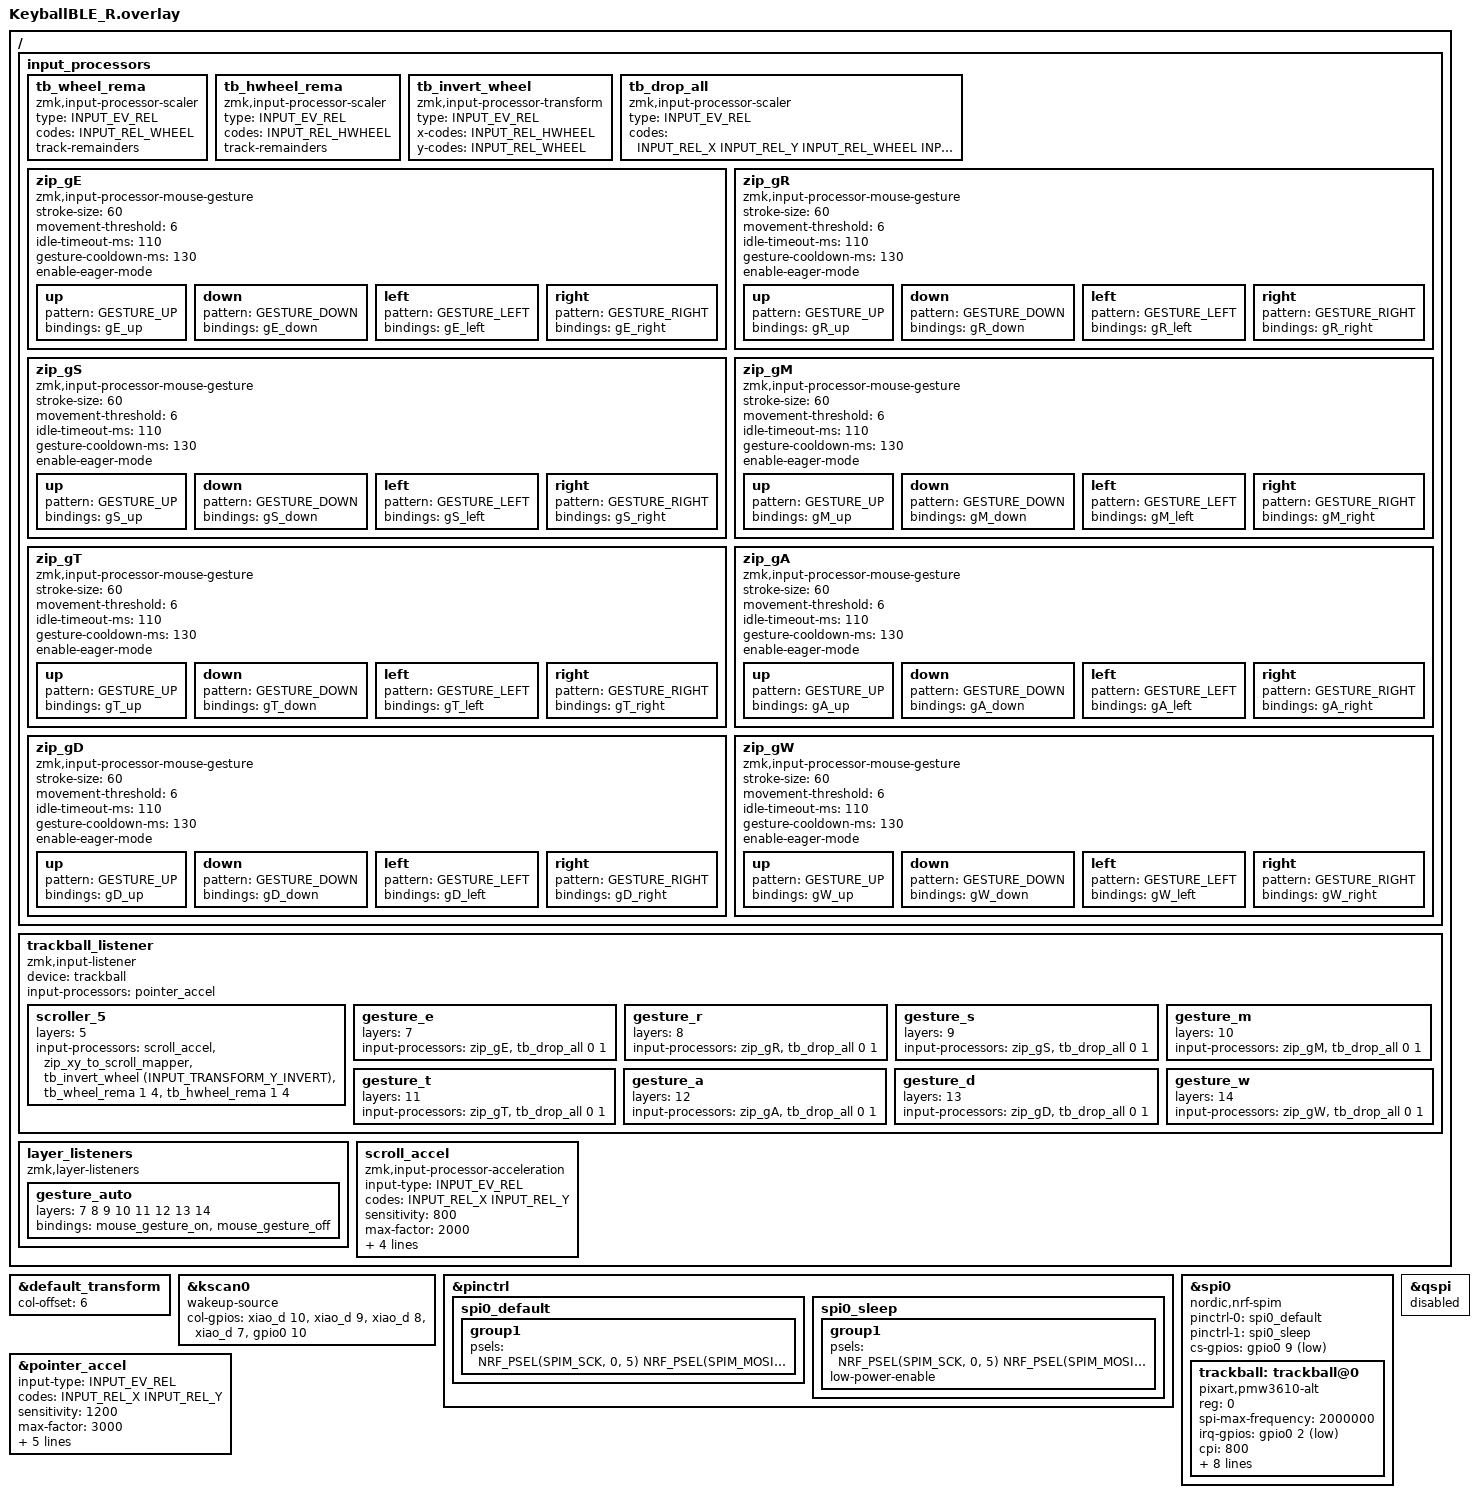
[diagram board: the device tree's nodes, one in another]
/* ===============================
 * KeyballBLE_R.overlay
 *
 *  - SCROLL(layer5)  : overlay side (zip_xy_to_scroll_mapper)
 *  - SNIPE(layer15)  : driver side (snipe-layers)
 *  - gesture(7-14)   : gesture recognition + REL stop
 *  - arrows(layer3)  : trackball to arrow keys
 * =============================== */

#include "KeyballBLE.dtsi"

#include <input/processors.dtsi>
#include <mouse-gesture.dtsi>
#include <behaviors/input_gestures_accel.dtsi>

#include <zephyr/dt-bindings/input/input-event-codes.h>
#include <dt-bindings/gpio/gpio.h>
#include <dt-bindings/zmk/keys.h>
#include <dt-bindings/zmk/mouse.h>
#include <dt-bindings/zmk/input_transform.h>

&default_transform { col-offset = <6>; };

&kscan0 {
    wakeup-source;
    col-gpios =
        <&xiao_d 10 GPIO_ACTIVE_HIGH>,
        <&xiao_d 9  GPIO_ACTIVE_HIGH>,
        <&xiao_d 8  GPIO_ACTIVE_HIGH>,
        <&xiao_d 7  GPIO_ACTIVE_HIGH>,
        <&gpio0  10 GPIO_ACTIVE_HIGH>;
};

/ {
    input_processors {
        tb_wheel_rema: tb_wheel_rema {
            compatible = "zmk,input-processor-scaler";
            #input-processor-cells = <2>;
            type = <INPUT_EV_REL>;
            codes = <INPUT_REL_WHEEL>;
            track-remainders;
        };

        tb_hwheel_rema: tb_hwheel_rema {
            compatible = "zmk,input-processor-scaler";
            #input-processor-cells = <2>;
            type = <INPUT_EV_REL>;
            codes = <INPUT_REL_HWHEEL>;
            track-remainders;
        };

        tb_invert_wheel: tb_invert_wheel {
            compatible = "zmk,input-processor-transform";
            #input-processor-cells = <1>;
            type = <INPUT_EV_REL>;
            x-codes = <INPUT_REL_HWHEEL>;
            y-codes = <INPUT_REL_WHEEL>;
        };

        tb_drop_all: tb_drop_all {
            compatible = "zmk,input-processor-scaler";
            #input-processor-cells = <2>;
            type = <INPUT_EV_REL>;
            codes = <INPUT_REL_X INPUT_REL_Y INPUT_REL_WHEEL INPUT_REL_HWHEEL>;
        };

        zip_gE: zip_gE {
            compatible = "zmk,input-processor-mouse-gesture";
            #input-processor-cells = <0>;
            stroke-size = <60>;
            movement-threshold = <6>;
            idle-timeout-ms = <110>;
            gesture-cooldown-ms = <130>;
            enable-eager-mode;
            up    { pattern = <GESTURE_UP>;    bindings = <&gE_up>;    };
            down  { pattern = <GESTURE_DOWN>;  bindings = <&gE_down>;  };
            left  { pattern = <GESTURE_LEFT>;  bindings = <&gE_left>;  };
            right { pattern = <GESTURE_RIGHT>; bindings = <&gE_right>; };
        };

        zip_gR: zip_gR {
            compatible = "zmk,input-processor-mouse-gesture";
            #input-processor-cells = <0>;
            stroke-size = <60>;
            movement-threshold = <6>;
            idle-timeout-ms = <110>;
            gesture-cooldown-ms = <130>;
            enable-eager-mode;
            up    { pattern = <GESTURE_UP>;    bindings = <&gR_up>;    };
            down  { pattern = <GESTURE_DOWN>;  bindings = <&gR_down>;  };
            left  { pattern = <GESTURE_LEFT>;  bindings = <&gR_left>;  };
            right { pattern = <GESTURE_RIGHT>; bindings = <&gR_right>; };
        };

        zip_gS: zip_gS {
            compatible = "zmk,input-processor-mouse-gesture";
            #input-processor-cells = <0>;
            stroke-size = <60>;
            movement-threshold = <6>;
            idle-timeout-ms = <110>;
            gesture-cooldown-ms = <130>;
            enable-eager-mode;
            up    { pattern = <GESTURE_UP>;    bindings = <&gS_up>;    };
            down  { pattern = <GESTURE_DOWN>;  bindings = <&gS_down>;  };
            left  { pattern = <GESTURE_LEFT>;  bindings = <&gS_left>;  };
            right { pattern = <GESTURE_RIGHT>; bindings = <&gS_right>; };
        };

        zip_gM: zip_gM {
            compatible = "zmk,input-processor-mouse-gesture";
            #input-processor-cells = <0>;
            stroke-size = <60>;
            movement-threshold = <6>;
            idle-timeout-ms = <110>;
            gesture-cooldown-ms = <130>;
            enable-eager-mode;
            up    { pattern = <GESTURE_UP>;    bindings = <&gM_up>;    };
            down  { pattern = <GESTURE_DOWN>;  bindings = <&gM_down>;  };
            left  { pattern = <GESTURE_LEFT>;  bindings = <&gM_left>;  };
            right { pattern = <GESTURE_RIGHT>; bindings = <&gM_right>; };
        };

        zip_gT: zip_gT {
            compatible = "zmk,input-processor-mouse-gesture";
            #input-processor-cells = <0>;
            stroke-size = <60>;
            movement-threshold = <6>;
            idle-timeout-ms = <110>;
            gesture-cooldown-ms = <130>;
            enable-eager-mode;
            up    { pattern = <GESTURE_UP>;    bindings = <&gT_up>;    };
            down  { pattern = <GESTURE_DOWN>;  bindings = <&gT_down>;  };
            left  { pattern = <GESTURE_LEFT>;  bindings = <&gT_left>;  };
            right { pattern = <GESTURE_RIGHT>; bindings = <&gT_right>; };
        };

        zip_gA: zip_gA {
            compatible = "zmk,input-processor-mouse-gesture";
            #input-processor-cells = <0>;
            stroke-size = <60>;
            movement-threshold = <6>;
            idle-timeout-ms = <110>;
            gesture-cooldown-ms = <130>;
            enable-eager-mode;
            up    { pattern = <GESTURE_UP>;    bindings = <&gA_up>;    };
            down  { pattern = <GESTURE_DOWN>;  bindings = <&gA_down>;  };
            left  { pattern = <GESTURE_LEFT>;  bindings = <&gA_left>;  };
            right { pattern = <GESTURE_RIGHT>; bindings = <&gA_right>; };
        };

        zip_gD: zip_gD {
            compatible = "zmk,input-processor-mouse-gesture";
            #input-processor-cells = <0>;
            stroke-size = <60>;
            movement-threshold = <6>;
            idle-timeout-ms = <110>;
            gesture-cooldown-ms = <130>;
            enable-eager-mode;
            up    { pattern = <GESTURE_UP>;    bindings = <&gD_up>;    };
            down  { pattern = <GESTURE_DOWN>;  bindings = <&gD_down>;  };
            left  { pattern = <GESTURE_LEFT>;  bindings = <&gD_left>;  };
            right { pattern = <GESTURE_RIGHT>; bindings = <&gD_right>; };
        };

        zip_gW: zip_gW {
            compatible = "zmk,input-processor-mouse-gesture";
            #input-processor-cells = <0>;
            stroke-size = <60>;
            movement-threshold = <6>;
            idle-timeout-ms = <110>;
            gesture-cooldown-ms = <130>;
            enable-eager-mode;
            up    { pattern = <GESTURE_UP>;    bindings = <&gW_up>;    };
            down  { pattern = <GESTURE_DOWN>;  bindings = <&gW_down>;  };
            left  { pattern = <GESTURE_LEFT>;  bindings = <&gW_left>;  };
            right { pattern = <GESTURE_RIGHT>; bindings = <&gW_right>; };
        };
    };

    trackball_listener: trackball_listener {
        compatible = "zmk,input-listener";
        device = <&trackball>;
        input-processors = <&pointer_accel>;

        scroller_5 { layers = <5>; input-processors = <&scroll_accel &zip_xy_to_scroll_mapper &tb_invert_wheel (INPUT_TRANSFORM_Y_INVERT) &tb_wheel_rema 1 4 &tb_hwheel_rema 1 4>; };

        gesture_e { layers = <7>;  input-processors = <&zip_gE &tb_drop_all 0 1>; };
        gesture_r { layers = <8>;  input-processors = <&zip_gR &tb_drop_all 0 1>; };
        gesture_s { layers = <9>;  input-processors = <&zip_gS &tb_drop_all 0 1>; };
        gesture_m { layers = <10>; input-processors = <&zip_gM &tb_drop_all 0 1>; };
        gesture_t { layers = <11>; input-processors = <&zip_gT &tb_drop_all 0 1>; };
        gesture_a { layers = <12>; input-processors = <&zip_gA &tb_drop_all 0 1>; };
        gesture_d { layers = <13>; input-processors = <&zip_gD &tb_drop_all 0 1>; };
        gesture_w { layers = <14>; input-processors = <&zip_gW &tb_drop_all 0 1>; };
    };

    layer_listeners {
        compatible = "zmk,layer-listeners";
        gesture_auto { layers = <7 8 9 10 11 12 13 14>; bindings = <&mouse_gesture_on &mouse_gesture_off>; };
    };
};

&pinctrl {
    spi0_default: spi0_default {
        group1 { psels = <NRF_PSEL(SPIM_SCK, 0, 5) NRF_PSEL(SPIM_MOSI, 0, 4) NRF_PSEL(SPIM_MISO, 0, 4)>; };
    };
    spi0_sleep: spi0_sleep {
        group1 { psels = <NRF_PSEL(SPIM_SCK, 0, 5) NRF_PSEL(SPIM_MOSI, 0, 4) NRF_PSEL(SPIM_MISO, 0, 4)>; low-power-enable; };
    };
};

&spi0 {
    status = "okay";
    compatible = "nordic,nrf-spim";
    pinctrl-0 = <&spi0_default>;
    pinctrl-1 = <&spi0_sleep>;
    pinctrl-names = "default", "sleep";
    cs-gpios = <&gpio0 9 GPIO_ACTIVE_LOW>;

    trackball: trackball@0 {
        status = "okay";
        compatible = "pixart,pmw3610-alt";
        reg = <0>;
        spi-max-frequency = <2000000>;
        irq-gpios    = <&gpio0 2 (GPIO_ACTIVE_LOW | GPIO_PULL_UP)>;
        cpi = <800>;
        force-awake;
        force-awake-4ms-mode;
        snipe-layers  = <15>;
        arrows-layers = <3>;
        arrows-tick   = <10>;
        evt-type     = <INPUT_EV_REL>;
        x-input-code = <INPUT_REL_X>;
        y-input-code = <INPUT_REL_Y>;
    };
};

&qspi {
    status = "disabled";
};

&pointer_accel {
    input-type = <INPUT_EV_REL>;
    codes = <INPUT_REL_X INPUT_REL_Y>;
    sensitivity = <1200>;
    max-factor = <3000>;
    acceleration-exponent = <2>;
    speed-threshold = <600>;
    speed-max = <3500>;
    min-factor = <1000>;
    sensor-dpi = <800>;
};

/ {
    scroll_accel: scroll_accel {
        compatible = "zmk,input-processor-acceleration";
        #input-processor-cells = <0>;
        input-type = <INPUT_EV_REL>;
        codes = <INPUT_REL_X INPUT_REL_Y>;
        sensitivity = <800>;
        max-factor = <2000>;
        acceleration-exponent = <1>;
        speed-threshold = <300>;
        speed-max = <2000>;
        sensor-dpi = <800>;
    };
};
